# 3066MNPIRH register map
File version: 1.0
Registers are 32-bit, access per field, reset 0x0 unless marked. A register's access mark holds for its fields unless they carry their own. Offsets are from the block's base; [hi:lo] are bit positions; {n}, {i} and the like mark numbered series.

## PMC — PMC peripheral interface
Base 0x147E0000
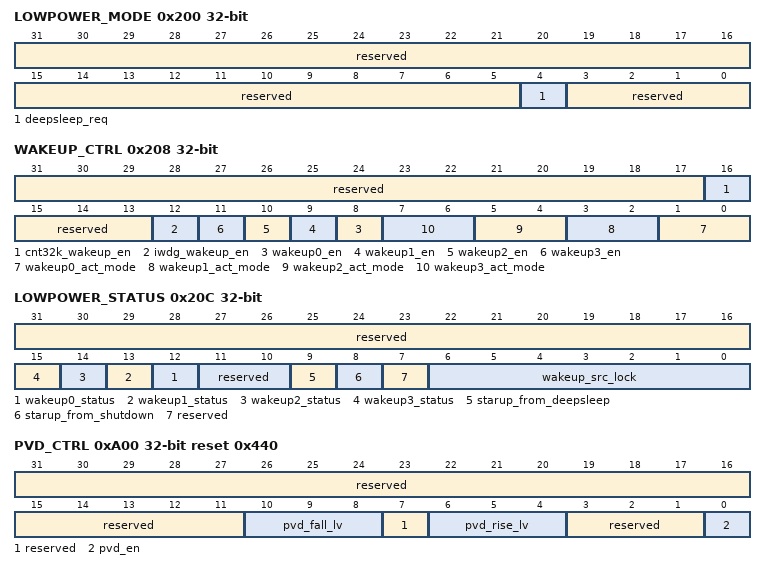
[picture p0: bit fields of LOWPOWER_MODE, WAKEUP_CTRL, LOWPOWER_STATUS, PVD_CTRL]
0x200 LOWPOWER_MODE — LOWPOWER_MODE为低功耗模式控制寄存器。
  [31:5] reserved ro — 保留。
  [4] deepsleep_req wo — 系统进入deepsleep模式请求。 对此寄存器位域写1操作将触发MCU进入deepsleep模式流程。
  [3:0] reserved ro — 保留。
0x204 CNT32K_WAKE_CYC rw reset 0xFFFF — CNT32K_WAKE_CYC为定时唤醒周期设置寄存器。
  [31:0] cnt32k_wakeup_cycle — 定时唤醒周期数（计数时钟clk_losc）。
0x208 WAKEUP_CTRL — WAKEUP_CTRL为deepsleep模式唤醒控制寄存器。
  [31:17] reserved ro — 保留。
  [16] cnt32k_wakeup_en rw — 定时唤醒使能。 0：不使能； 1：使能。
  [15:13] reserved ro — 保留。
  [12] iwdg_wakeup_en rw — IWDG唤醒使能。 0：不使能； 1：使能。
  [n+8] wakeup{n}_en rw (n=0..3) — WAKEUP{n}使能。 0：不使能； 1：使能。
  [2n+1:2n] wakeup{n}_act_mode rw (n=0..3) — WAKEUP{n}有效模式选择。 00：上升沿有效； 01：下降沿有效； 10：高电平有效； 11：低电平有效。
0x20C LOWPOWER_STATUS ro — LOWPOWER_STATUS为低功耗状态查询寄存器。
  [31:16] reserved — 保留。
  [n+12] wakeup{n}_status (n=0..3) — wakeup{n}唤醒源状态。 0：唤醒源低电平； 1：唤醒源高电平。
  [11:10] reserved — 保留。
  [9] starup_from_deepsleep — 从deepsleep状态启动标识。 0：未从deepsleep模式启动； 1：从deepsleep模式启动。
  [8] starup_from_shutdown — MCU初次上电启动标识。 0：不是初次上电启动； 1：是初次上电启动。
  [7] reserved — 保留。
  [6:0] wakeup_src_lock — 启动唤醒源查询。 bit[6]：IWDG唤醒； bit[5]：RESETN管脚唤醒； bit[4]：WAKEUP3唤醒； bit[3]：WAKEUP2唤醒； bit[2]：WAKEUP1唤醒； bit[1]：WAKEUP0唤醒； bit[0]：cnt32k定时唤醒。
0xA00 PVD_CTRL reset 0x440 — PVD_CTRL为PVD控制寄存器。
  [31:11] reserved ro — 保留。
  [10:8] pvd_fall_lv rw — PVD下降沿阈值。 000：2.08V； 001：2.18V； 010：2.78V； 011：2.38V； 100：2.48V； 101：2.58V； 110：2.68V； 111：2.78V。
  [7] reserved ro — 保留。
  [6:4] pvd_rise_lv rw — PVD上升沿阈值。 000：2.18V； 001：2.28V； 010：2.38V； 011：2.48V； 100：2.58V； 101：2.68V； 110：2.78V； 111：2.88V。
  [3:1] reserved ro — 保留。
  [0] pvd_en rw — PVD使能。 0：不使能； 1：使能。
{0xF00+4i} AON_USER_REG{i} rw (i=0..3) — AON_USER_REG{i}为AON域用户寄存器{i}。
  [31:0] aon_user_reg{i} — AON电源域通用寄存器{i}。

## CFD — CFD peripheral interface
Base 0x10020000
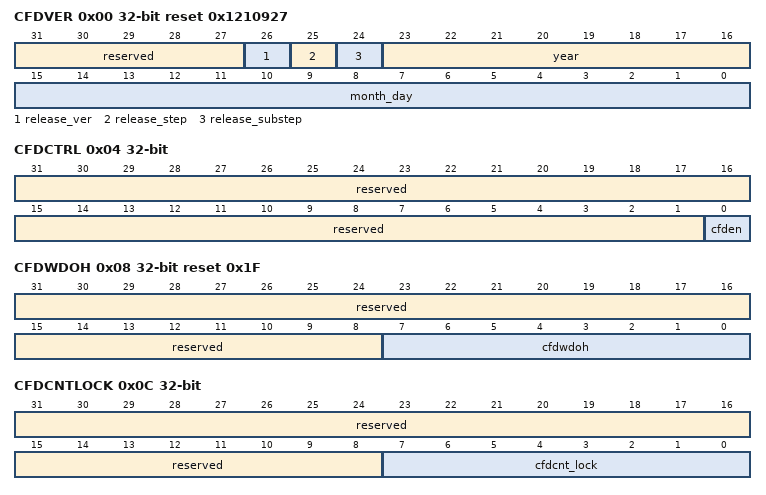
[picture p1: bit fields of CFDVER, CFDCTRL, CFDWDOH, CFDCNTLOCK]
0x00 CFDVER ro reset 0x1210927 — CFDVER为CFD Version，CFD版本信息寄存器。
  [31:27] reserved — 保留。
  [26] release_ver — 版本信息。
  [25] release_step — 版本信息。
  [24] release_substep — 版本信息。
  [23:16] year — 年。
  [15:0] month_day — 月日。
0x04 CFDCTRL — CFDCTRL为CFD Control，CFD控制寄存器。
  [31:1] reserved ro — 保留。
  [0] cfden rw — CFD使能。 0：不使能； 1：使能。
0x08 CFDWDOH reset 0x1F — CFDWDOH为CFD Check Window High Value，CFD检查窗口上限寄存器。
  [31:8] reserved ro — 保留。
  [7:0] cfdwdoh rw — CFD检查窗口上界限，默认为32（从0x0计数到0x1F）个LOSC周期，即检测时间1ms，CFDCNTLOCK大于等于该值说明检测到PLL参考时钟失效（Clock_fail）。
0x0C CFDCNTLOCK ro — CFDCNTLOCK为CFD Count Lock Value，CFD计数锁存值寄存器。
  [31:8] reserved — 保留。
  [7:0] cfdcnt_lock — CFD内部计数器计数锁存值。
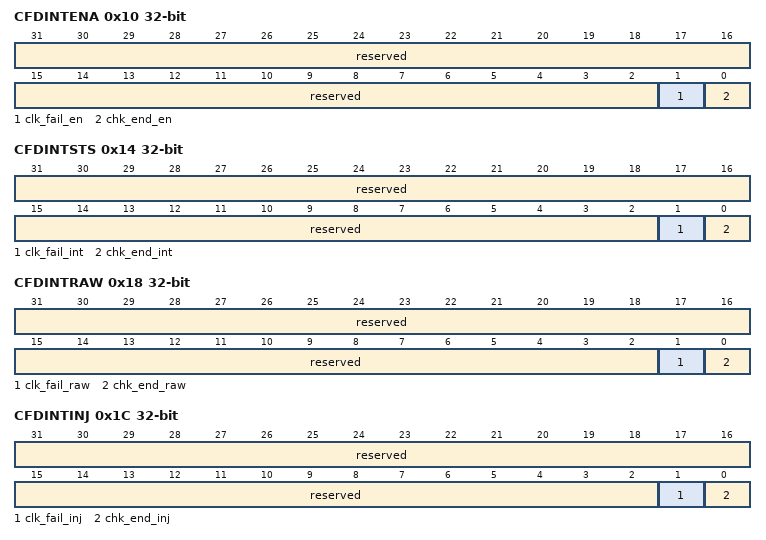
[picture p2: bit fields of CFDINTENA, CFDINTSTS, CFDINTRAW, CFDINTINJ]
0x10 CFDINTENA — CFDINTENA为CFD Interrupt Enable，CFD中断使能寄存器。
  [31:2] reserved ro — 保留。
  [1] clk_fail_en rw — CFD检测到PLL参考时钟失效中断使能。不使能时，即屏蔽相应的中断状态，不影响相应的原始中断。若全部不使能，CFD不会上报中断给CPU。 0：不使能； 1：使能。
  [0] chk_end_en rw — CFD 检测结束中断使能。 0：不使能； 1：使能。
0x14 CFDINTSTS ro — CFDINTSTS为CFD Interrupt Status，CFD中断状态寄存器。
  [31:2] reserved — 保留。
  [1] clk_fail_int — CFD检测到PLL参考时钟失效中断。 0：无中断； 1：有中断。
  [0] chk_end_int — CFD检测结束中断。 0：无中断； 1：有中断。
0x18 CFDINTRAW — CFDINTRAW为CFD Raw Interrupt，CFD原始中断寄存器。
  [31:2] reserved ro — 保留。
  [1] clk_fail_raw rw write-clears — CFD检测到PLL参考时钟失效原始中断。当CFDCTRL[cfden]为1时，才可能产生此中断。 0：无原始中断； 1：有原始中断。写1清除中断。
  [0] chk_end_raw rw write-clears — CFD 检测结束中断原始中断。当CFDCTRL[cfden]为1时，才可能产生此中断。 0：无原始中断； 1：有原始中断。写1清除中断。
0x1C CFDINTINJ — CFDINTINJ为CFD Interrupt Injection，CFD中断注入寄存器。
  [31:2] reserved ro — 保留。
  [1] clk_fail_inj rw write-1-clears — CFD检测到PLL参考时钟失效中断注入。 0：不注入； 1：注入。
  [0] chk_end_inj rw write-1-clears — CFD检测结束中断注入。 0：不注入； 1：注入。

## CMM — CMM peripheral interface
Base 0x10010000
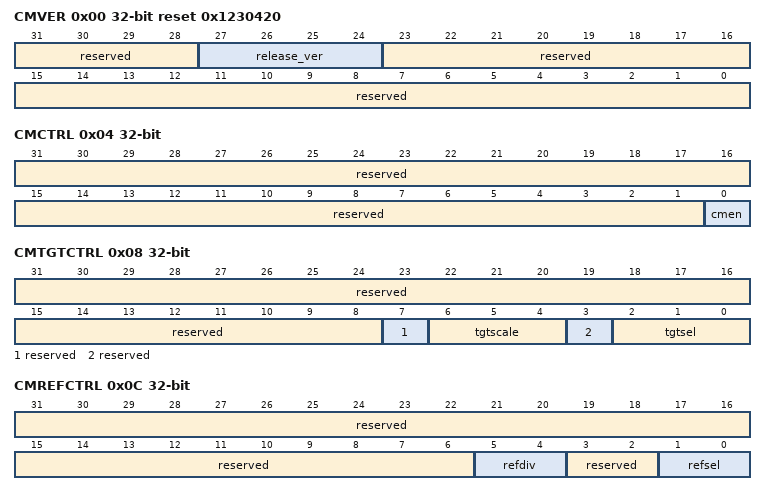
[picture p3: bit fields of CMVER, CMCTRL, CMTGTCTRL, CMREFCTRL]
0x00 CMVER ro reset 0x1230420 — CMVER为CMM Version，CMM版本信息寄存器。
  [31:28] reserved — 保留。
  [27:24] release_ver — 版本信息。
  [23:0] reserved — 保留。
0x04 CMCTRL — CMCTRL为CMM Control，CMM控制寄存器。
  [31:1] reserved ro — 保留。
  [0] cmen rw — CMM使能。 0：不使能； 1：使能。
0x08 CMTGTCTRL — CMTGTCTRL为CMM Target Clock Control，CMM目标时钟控制寄存器。
  [31:8] reserved ro — 保留。
  [7] reserved ro — 保留。
  [6:4] tgtscale rw — CMM目标时钟分频系数，偶数倍占空比50%分频，CMM使用分频后的时钟作为被监控对象。 000：不分频； 001：32分频； 010：128分频； 011：1024分频； 100：8192分频； 其他：8192分频。
  [3] reserved ro — 保留。
  [2:0] tgtsel rw — CMM目标时钟源选择。 000：目标时钟源0，clk_losc； 001：目标时钟源1，clk_hosc； 010：目标时钟源2，clk_xtal； 011：目标时钟源3，clk_sys； 其他：保留。
0x0C CMREFCTRL — CMREFCTRL为CMM Reference Clock Control，CMM参考时钟控制寄存器。
  [31:6] reserved ro — 保留。
  [5:4] refdiv rw — CMM参考时钟分频系数，CMM使用分频后的时钟作为监控参考。 00：不分频； 01：4分频； 10：8分频； 11：32分频。
  [3:2] reserved ro — 保留。
  [1:0] refsel rw — CMM 参考时钟源选择。 00：参考时钟源0，clk_losc； 01：参考时钟源1，clk_hosc； 10：参考时钟源2，clk_xtal； 11：参考时钟源3，clk_sys。
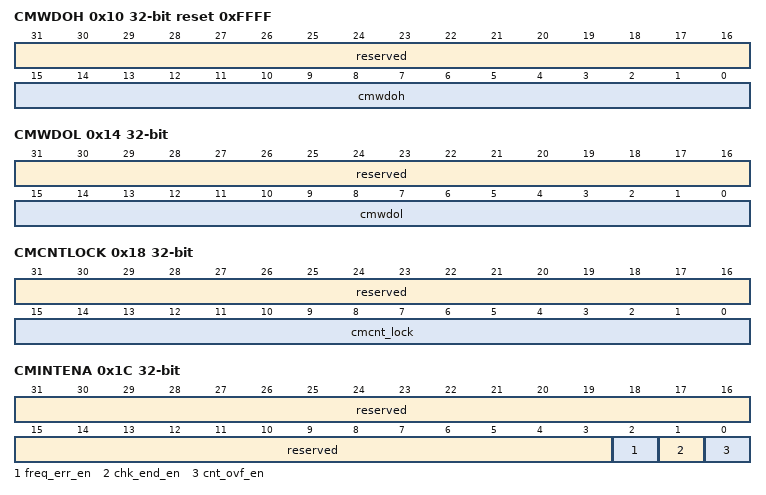
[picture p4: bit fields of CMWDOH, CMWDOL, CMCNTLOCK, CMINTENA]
0x10 CMWDOH reset 0xFFFF — CMWDOH为CMM Check Window High，CMM检查窗口上限寄存器。
  [31:16] reserved ro — 保留。
  [15:0] cmwdoh rw — CMM检查窗口上界限，CMCNT大于该值说明频率错误。
0x14 CMWDOL — CMWDOL为CMM Check Window Low，CMM检查窗口下限寄存器。
  [31:16] reserved ro — 保留。
  [15:0] cmwdol rw — CMM检查窗口下界限，CMCNT小于该值说明频率错误。
0x18 CMCNTLOCK ro — CMCNTLOCK为CMM Count Locked Value，CMM计数锁存值寄存器。
  [31:16] reserved — 保留。
  [15:0] cmcnt_lock — CMM 内部计数器计数锁存值。
0x1C CMINTENA — CMINTENA为CMM Interrupt Enable，CMM中断使能寄存器。
  [31:3] reserved ro — 保留。
  [2] freq_err_en rw — CMM频率错误中断使能。不使能时，即屏蔽相应的中断状态，不影响相应的原始中断。若全部不使能，CMM不会上报中断给CPU。 0：不使能； 1：使能。
  [1] chk_end_en rw — CMM检测结束中断使能。不使能时，即屏蔽相应的中断状态，不影响相应的原始中断。若全部不使能，CMM不会上报中断给CPU。 0：不使能； 1：使能。
  [0] cnt_ovf_en rw — CMM计数溢出中断使能。不使能时，即屏蔽相应的中断状态，不影响相应的原始中断。若全部不使能，CMM不会上报中断给CPU。 0：不使能； 1：使能。
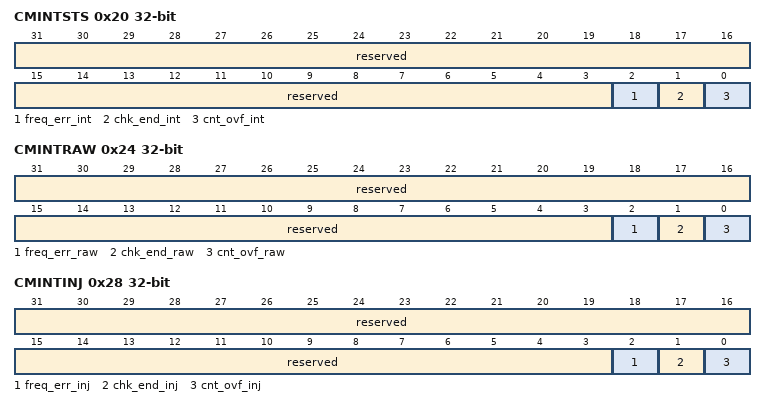
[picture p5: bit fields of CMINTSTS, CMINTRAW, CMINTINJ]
0x20 CMINTSTS ro — CMINTSTS为CMM Interrupt Status，CMM中断状态寄存器。
  [31:3] reserved — 保留。
  [2] freq_err_int — CMM频率错误中断状态。 0：无中断； 1：有中断。
  [1] chk_end_int — CMM检测结束中断状态。 0：无中断； 1：有中断。
  [0] cnt_ovf_int — CMM计数溢出中断状态。 0：无中断； 1：有中断。
0x24 CMINTRAW — CMINTRAW为CMM Raw Interrupt，CMM原始中断寄存器。
  [31:3] reserved ro — 保留。
  [2] freq_err_raw rw write-clears — CMM频率错误原始中断。当CMCTRL[cmen]为1时，才可能产生此中断。 0：无原始中断； 1：有原始中断。写1清除中断。
  [1] chk_end_raw rw write-clears — CMM检测结束中断原始中断。当CMCTRL[cmen]为1时，才可能产生此中断。 0：无原始中断； 1：有原始中断。写1清除中断。
  [0] cnt_ovf_raw rw write-clears — CMM 计数溢出中断原始中断。当CMCTRL[cmen]为1时，才可能产生此中断。 0：无原始中断； 1：有原始中断。写1清除中断。
0x28 CMINTINJ — CMINTINJ为CMM Interrupt Injection，CMM中断注入寄存器。
  [31:3] reserved ro — 保留。
  [2] freq_err_inj rw write-1-clears — CMM频率错误中断注入。 0：不注入； 1：注入。
  [1] chk_end_inj rw write-1-clears — CMM检测结束中断注入。 0：不注入； 1：注入。
  [0] cnt_ovf_inj rw write-1-clears — CMM计数溢出中断注入。 0：不注入； 1：注入。
